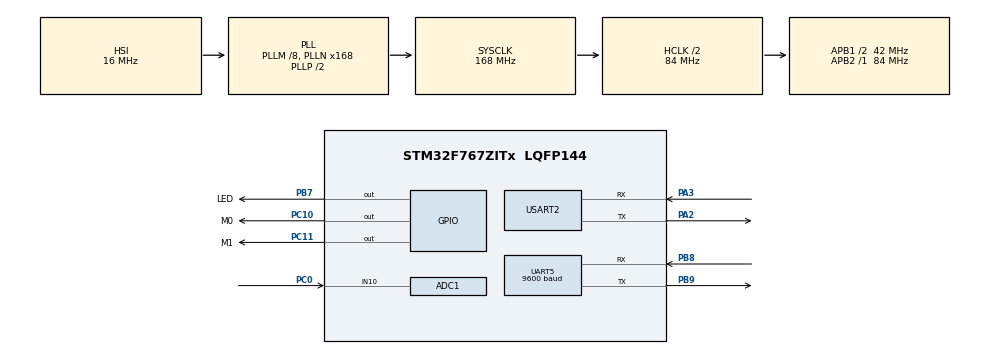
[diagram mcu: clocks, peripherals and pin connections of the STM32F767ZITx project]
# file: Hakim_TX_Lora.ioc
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ADC1.Channel-0\#ChannelRegularConversion=ADC_CHANNEL_10
ADC1.NbrOfConversionFlag=1
ADC1.Rank-0\#ChannelRegularConversion=1
ADC1.SamplingTime-0\#ChannelRegularConversion=ADC_SAMPLETIME_3CYCLES
ADC1.master=1
Mcu.Family=STM32F7
Mcu.Name=STM32F767ZITx
Mcu.Package=LQFP144
NVIC.PriorityGroup=NVIC_PRIORITYGROUP_4
NVIC.UART5_IRQn=true\:0\:0\:false\:false\:true\:true\:true\:true
PA13.Mode=Serial_Wire
PA13.Signal=SYS_JTMS-SWDIO
PA14.Mode=Serial_Wire
PA14.Signal=SYS_JTCK-SWCLK
PA2.Mode=Asynchronous
PA2.Signal=USART2_TX
PA3.Mode=Asynchronous
PA3.Signal=USART2_RX
PB7.GPIO_Label=LED
PB7.Signal=GPIO_Output
PB8.Mode=Asynchronous
PB8.Signal=UART5_RX
PB9.Mode=Asynchronous
PB9.Signal=UART5_TX
PC0.Signal=ADCx_IN10
PC10.GPIO_Label=M0
PC10.Signal=GPIO_Output
PC11.GPIO_Label=M1
PC11.Signal=GPIO_Output
ProjectManager.HeapSize=0x200
ProjectManager.StackSize=0x400
ProjectManager.TargetToolchain=STM32CubeIDE
RCC.AHBCLKDivider=RCC_SYSCLK_DIV2
RCC.AHBFreq_Value=84000000
RCC.APB1CLKDivider=RCC_HCLK_DIV2
RCC.APB1Freq_Value=42000000
RCC.APB1TimFreq_Value=84000000
RCC.APB2Freq_Value=84000000
RCC.APB2TimFreq_Value=84000000
RCC.CortexFreq_Value=84000000
RCC.HCLKFreq_Value=84000000
RCC.HSE_VALUE=25000000
RCC.HSI_VALUE=16000000
RCC.LSE_VALUE=32768
RCC.PLLM=8
RCC.PLLN=168
RCC.SYSCLKFreq_VALUE=168000000
RCC.SYSCLKSource=RCC_SYSCLKSOURCE_PLLCLK
RCC.USBFreq_Value=168000000
RCC.VCOOutputFreq_Value=336000000
SH.ADCx_IN10.0=ADC1_IN10,IN10
UART5.BaudRate=9600
USART2.VirtualMode-Asynchronous=VM_ASYNC
board=custom

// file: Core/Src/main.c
/* USER CODE BEGIN Header */
/**
  ******************************************************************************
  * @file           : main.c
  * @brief          : Main program body
  ******************************************************************************
  * @attention
  *
  * Copyright (c) 2024 STMicroelectronics.
  * All rights reserved.
  *
  * This software is licensed under terms that can be found in the LICENSE file
  * in the root directory of this software component.
  * If no LICENSE file comes with this software, it is provided AS-IS.
  *
  ******************************************************************************
  */
/* USER CODE END Header */
#include "main.h"

/* USER CODE BEGIN Includes */
#include "Lora.h"
/* USER CODE END Includes */

ADC_HandleTypeDef hadc1;

UART_HandleTypeDef huart5;
UART_HandleTypeDef huart2;

void SystemClock_Config(void);
static void MX_GPIO_Init(void);
static void MX_ADC1_Init(void);
static void MX_UART5_Init(void);
static void MX_USART2_UART_Init(void);

/* USER CODE BEGIN 0 */
char rx;
/* USER CODE END 0 */

int main(void)
{

  /* MCU Configuration--------------------------------------------------------*/

  /* Reset of all peripherals, Initializes the Flash interface and the Systick. */
  HAL_Init();

  /* Configure the system clock */
  SystemClock_Config();

  /* Initialize all configured peripherals */
  MX_GPIO_Init();
  MX_ADC1_Init();
  MX_UART5_Init();
  MX_USART2_UART_Init();
  /* USER CODE BEGIN 2 */
  Lora_Init();
  HAL_UART_Receive_IT(&huart5,&rx, 1);
  /* USER CODE END 2 */

  /* Infinite loop */
  /* USER CODE BEGIN WHILE */
  while (1)
  {

	  Lora_Tx();
	  HAL_Delay(1000);
    /* USER CODE END WHILE */

  }
}

void SystemClock_Config(void)
{
  RCC_OscInitTypeDef RCC_OscInitStruct = {0};
  RCC_ClkInitTypeDef RCC_ClkInitStruct = {0};

  /** Configure the main internal regulator output voltage
  */
  __HAL_RCC_PWR_CLK_ENABLE();
  __HAL_PWR_VOLTAGESCALING_CONFIG(PWR_REGULATOR_VOLTAGE_SCALE3);

  /** Initializes the RCC Oscillators according to the specified parameters
  * in the RCC_OscInitTypeDef structure.
  */
  RCC_OscInitStruct.OscillatorType = RCC_OSCILLATORTYPE_HSI;
  RCC_OscInitStruct.HSIState = RCC_HSI_ON;
  RCC_OscInitStruct.HSICalibrationValue = RCC_HSICALIBRATION_DEFAULT;
  RCC_OscInitStruct.PLL.PLLState = RCC_PLL_ON;
  RCC_OscInitStruct.PLL.PLLSource = RCC_PLLSOURCE_HSI;
  RCC_OscInitStruct.PLL.PLLM = 8;
  RCC_OscInitStruct.PLL.PLLN = 168;
  RCC_OscInitStruct.PLL.PLLP = RCC_PLLP_DIV2;
  RCC_OscInitStruct.PLL.PLLQ = 2;
  RCC_OscInitStruct.PLL.PLLR = 2;
  if (HAL_RCC_OscConfig(&RCC_OscInitStruct) != HAL_OK)
  {
    Error_Handler();
  }

  /** Initializes the CPU, AHB and APB buses clocks
  */
  RCC_ClkInitStruct.ClockType = RCC_CLOCKTYPE_HCLK|RCC_CLOCKTYPE_SYSCLK
                              |RCC_CLOCKTYPE_PCLK1|RCC_CLOCKTYPE_PCLK2;
  RCC_ClkInitStruct.SYSCLKSource = RCC_SYSCLKSOURCE_PLLCLK;
  RCC_ClkInitStruct.AHBCLKDivider = RCC_SYSCLK_DIV2;
  RCC_ClkInitStruct.APB1CLKDivider = RCC_HCLK_DIV2;
  RCC_ClkInitStruct.APB2CLKDivider = RCC_HCLK_DIV1;

  if (HAL_RCC_ClockConfig(&RCC_ClkInitStruct, FLASH_LATENCY_2) != HAL_OK)
  {
    Error_Handler();
  }
}

static void MX_ADC1_Init(void)
{

  ADC_ChannelConfTypeDef sConfig = {0};

  /** Configure the global features of the ADC (Clock, Resolution, Data Alignment and number of conversion)
  */
  hadc1.Instance = ADC1;
  hadc1.Init.ClockPrescaler = ADC_CLOCK_SYNC_PCLK_DIV4;
  hadc1.Init.Resolution = ADC_RESOLUTION_12B;
  hadc1.Init.ScanConvMode = ADC_SCAN_DISABLE;
  hadc1.Init.ContinuousConvMode = DISABLE;
  hadc1.Init.DiscontinuousConvMode = DISABLE;
  hadc1.Init.ExternalTrigConvEdge = ADC_EXTERNALTRIGCONVEDGE_NONE;
  hadc1.Init.ExternalTrigConv = ADC_SOFTWARE_START;
  hadc1.Init.DataAlign = ADC_DATAALIGN_RIGHT;
  hadc1.Init.NbrOfConversion = 1;
  hadc1.Init.DMAContinuousRequests = DISABLE;
  hadc1.Init.EOCSelection = ADC_EOC_SINGLE_CONV;
  if (HAL_ADC_Init(&hadc1) != HAL_OK)
  {
    Error_Handler();
  }

  /** Configure for the selected ADC regular channel its corresponding rank in the sequencer and its sample time.
  */
  sConfig.Channel = ADC_CHANNEL_10;
  sConfig.Rank = ADC_REGULAR_RANK_1;
  sConfig.SamplingTime = ADC_SAMPLETIME_3CYCLES;
  if (HAL_ADC_ConfigChannel(&hadc1, &sConfig) != HAL_OK)
  {
    Error_Handler();
  }

}

static void MX_UART5_Init(void)
{

  huart5.Instance = UART5;
  huart5.Init.BaudRate = 9600;
  huart5.Init.WordLength = UART_WORDLENGTH_8B;
  huart5.Init.StopBits = UART_STOPBITS_1;
  huart5.Init.Parity = UART_PARITY_NONE;
  huart5.Init.Mode = UART_MODE_TX_RX;
  huart5.Init.HwFlowCtl = UART_HWCONTROL_NONE;
  huart5.Init.OverSampling = UART_OVERSAMPLING_16;
  huart5.Init.OneBitSampling = UART_ONE_BIT_SAMPLE_DISABLE;
  huart5.AdvancedInit.AdvFeatureInit = UART_ADVFEATURE_NO_INIT;
  if (HAL_UART_Init(&huart5) != HAL_OK)
  {
    Error_Handler();
  }

}

static void MX_USART2_UART_Init(void)
{

  huart2.Instance = USART2;
  huart2.Init.BaudRate = 115200;
  huart2.Init.WordLength = UART_WORDLENGTH_8B;
  huart2.Init.StopBits = UART_STOPBITS_1;
  huart2.Init.Parity = UART_PARITY_NONE;
  huart2.Init.Mode = UART_MODE_TX_RX;
  huart2.Init.HwFlowCtl = UART_HWCONTROL_NONE;
  huart2.Init.OverSampling = UART_OVERSAMPLING_16;
  huart2.Init.OneBitSampling = UART_ONE_BIT_SAMPLE_DISABLE;
  huart2.AdvancedInit.AdvFeatureInit = UART_ADVFEATURE_NO_INIT;
  if (HAL_UART_Init(&huart2) != HAL_OK)
  {
    Error_Handler();
  }

}

static void MX_GPIO_Init(void)
{
  GPIO_InitTypeDef GPIO_InitStruct = {0};

  /* GPIO Ports Clock Enable */
  __HAL_RCC_GPIOC_CLK_ENABLE();
  __HAL_RCC_GPIOA_CLK_ENABLE();
  __HAL_RCC_GPIOB_CLK_ENABLE();

  /*Configure GPIO pin Output Level */
  HAL_GPIO_WritePin(GPIOC, M0_Pin|M1_Pin, GPIO_PIN_RESET);

  /*Configure GPIO pin Output Level */
  HAL_GPIO_WritePin(LED_GPIO_Port, LED_Pin, GPIO_PIN_RESET);

  /*Configure GPIO pins : M0_Pin M1_Pin */
  GPIO_InitStruct.Pin = M0_Pin|M1_Pin;
  GPIO_InitStruct.Mode = GPIO_MODE_OUTPUT_PP;
  GPIO_InitStruct.Pull = GPIO_NOPULL;
  GPIO_InitStruct.Speed = GPIO_SPEED_FREQ_LOW;
  HAL_GPIO_Init(GPIOC, &GPIO_InitStruct);

  /*Configure GPIO pin : LED_Pin */
  GPIO_InitStruct.Pin = LED_Pin;
  GPIO_InitStruct.Mode = GPIO_MODE_OUTPUT_PP;
  GPIO_InitStruct.Pull = GPIO_NOPULL;
  GPIO_InitStruct.Speed = GPIO_SPEED_FREQ_LOW;
  HAL_GPIO_Init(LED_GPIO_Port, &GPIO_InitStruct);

}

/* USER CODE BEGIN 4 */
void HAL_UART_RxCpltCallback(UART_HandleTypeDef *huart){

	if (rx=='a') HAL_GPIO_WritePin(LED_GPIO_Port, LED_Pin, 1);
	else if(rx=='b')HAL_GPIO_WritePin(LED_GPIO_Port, LED_Pin, 0);

	  HAL_UART_Receive_IT(&huart5,&rx, 1);
}
/* USER CODE END 4 */

void Error_Handler(void)
{
  __disable_irq();
  while (1)
  {
  }
}
